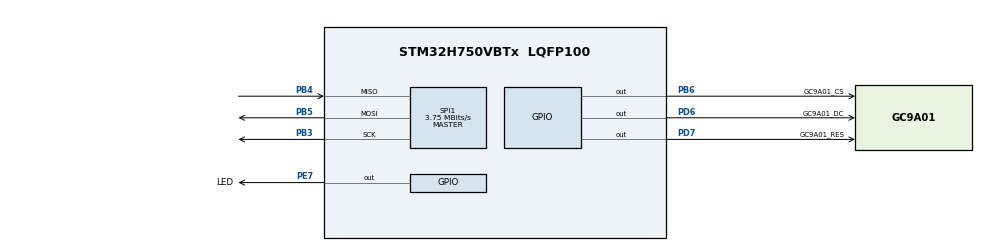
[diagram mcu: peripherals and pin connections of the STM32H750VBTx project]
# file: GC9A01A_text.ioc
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Mcu.Family=STM32H7
Mcu.Name=STM32H750VBTx
Mcu.Package=LQFP100
NVIC.PriorityGroup=NVIC_PRIORITYGROUP_4
NVIC.TIM17_IRQn=true\:15\:0\:false\:false\:true\:false\:true\:true
NVIC.TIM2_IRQn=true\:0\:0\:false\:false\:true\:true\:true\:true
NVIC.TimeBase=TIM17_IRQn
NVIC.TimeBaseIP=TIM17
PA13\ (JTMS/SWDIO).Mode=Serial_Wire
PA13\ (JTMS/SWDIO).Signal=DEBUG_JTMS-SWDIO
PA14\ (JTCK/SWCLK).Mode=Serial_Wire
PA14\ (JTCK/SWCLK).Signal=DEBUG_JTCK-SWCLK
PB3\ (JTDO/TRACESWO).Mode=Full_Duplex_Master
PB3\ (JTDO/TRACESWO).Signal=SPI1_SCK
PB4\ (NJTRST).Mode=Full_Duplex_Master
PB4\ (NJTRST).Signal=SPI1_MISO
PB5.Mode=Full_Duplex_Master
PB5.Signal=SPI1_MOSI
PB6.GPIO_Label=GC9A01_CS
PB6.Signal=GPIO_Output
PD6.GPIO_Label=GC9A01_DC
PD6.Signal=GPIO_Output
PD7.GPIO_Label=GC9A01_RES
PD7.Signal=GPIO_Output
PE7.GPIO_Label=LED
PE7.Signal=GPIO_Output
PH0-OSC_IN\ (PH0).Mode=HSE-External-Oscillator
PH0-OSC_IN\ (PH0).Signal=RCC_OSC_IN
PH1-OSC_OUT\ (PH1).Mode=HSE-External-Oscillator
PH1-OSC_OUT\ (PH1).Signal=RCC_OSC_OUT
ProjectManager.HeapSize=0x200
ProjectManager.StackSize=0x400
ProjectManager.TargetToolchain=STM32CubeIDE
RCC.ADCFreq_Value=50390625
RCC.APB1Freq_Value=120000000
RCC.APB2Freq_Value=120000000
RCC.APB3Freq_Value=120000000
RCC.APB4Freq_Value=120000000
RCC.CortexFreq_Value=240000000
RCC.D1PPRE=RCC_APB3_DIV2
RCC.D2PPRE1=RCC_APB1_DIV2
RCC.D2PPRE2=RCC_APB2_DIV2
RCC.D3PPRE=RCC_APB4_DIV2
RCC.DIVM1=5
RCC.DIVN1=96
RCC.DIVQ1=4
RCC.HCLKFreq_Value=240000000
RCC.PLLFRACN=0
RCC.PLLSourceVirtual=RCC_PLLSOURCE_HSE
RCC.SYSCLKFreq_VALUE=240000000
RCC.SYSCLKSource=RCC_SYSCLKSOURCE_PLLCLK
RCC.USBFreq_Value=120000000
SPI1.BaudRatePrescaler=SPI_BAUDRATEPRESCALER_32
SPI1.CalculateBaudRate=3.75 MBits/s
SPI1.DataSize=SPI_DATASIZE_8BIT
SPI1.Direction=SPI_DIRECTION_2LINES
SPI1.Mode=SPI_MODE_MASTER
SPI1.VirtualType=VM_MASTER
TIM2.Period=999
TIM2.Prescaler=239
VP_HRTIM_VS_hrtimMasterTimerNoOutput.Mode=MasterTimer
VP_SYS_VS_tim17.Mode=TIM17
VP_TIM2_VS_ClockSourceINT.Mode=Internal
board=custom

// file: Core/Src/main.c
/* USER CODE BEGIN Header */
/**
  ******************************************************************************
  * @file           : main.c
  * @brief          : Main program body
  ******************************************************************************
  * @attention
  *
  * Copyright (c) 2024 STMicroelectronics.
  * All rights reserved.
  *
  * This software is licensed under terms that can be found in the LICENSE file
  * in the root directory of this software component.
  * If no LICENSE file comes with this software, it is provided AS-IS.
  *
  ******************************************************************************
  */
/* USER CODE END Header */
#include "main.h"

HRTIM_HandleTypeDef hhrtim;

SPI_HandleTypeDef hspi1;

TIM_HandleTypeDef htim2;

void SystemClock_Config(void);
static void MX_GPIO_Init(void);
static void MX_HRTIM_Init(void);
static void MX_SPI1_Init(void);
static void MX_TIM2_Init(void);

int main(void)
{

  /* MCU Configuration--------------------------------------------------------*/

  /* Reset of all peripherals, Initializes the Flash interface and the Systick. */
  HAL_Init();

  /* Configure the system clock */
  SystemClock_Config();

  /* Initialize all configured peripherals */
  MX_GPIO_Init();
  MX_HRTIM_Init();
  MX_SPI1_Init();
  MX_TIM2_Init();
  /* USER CODE BEGIN 2 */
  setup();
  /* USER CODE END 2 */

  /* Infinite loop */
  while (1)
  {

    /* USER CODE BEGIN 3 */
	  loop();
  }
  /* USER CODE END 3 */
}

void SystemClock_Config(void)
{
  RCC_OscInitTypeDef RCC_OscInitStruct = {0};
  RCC_ClkInitTypeDef RCC_ClkInitStruct = {0};

  /** Supply configuration update enable
  */
  HAL_PWREx_ConfigSupply(PWR_LDO_SUPPLY);

  /** Configure the main internal regulator output voltage
  */
  __HAL_PWR_VOLTAGESCALING_CONFIG(PWR_REGULATOR_VOLTAGE_SCALE2);

  while(!__HAL_PWR_GET_FLAG(PWR_FLAG_VOSRDY)) {}

  /** Initializes the RCC Oscillators according to the specified parameters
  * in the RCC_OscInitTypeDef structure.
  */
  RCC_OscInitStruct.OscillatorType = RCC_OSCILLATORTYPE_HSE;
  RCC_OscInitStruct.HSEState = RCC_HSE_ON;
  RCC_OscInitStruct.PLL.PLLState = RCC_PLL_ON;
  RCC_OscInitStruct.PLL.PLLSource = RCC_PLLSOURCE_HSE;
  RCC_OscInitStruct.PLL.PLLM = 5;
  RCC_OscInitStruct.PLL.PLLN = 96;
  RCC_OscInitStruct.PLL.PLLP = 2;
  RCC_OscInitStruct.PLL.PLLQ = 4;
  RCC_OscInitStruct.PLL.PLLR = 2;
  RCC_OscInitStruct.PLL.PLLRGE = RCC_PLL1VCIRANGE_2;
  RCC_OscInitStruct.PLL.PLLVCOSEL = RCC_PLL1VCOWIDE;
  RCC_OscInitStruct.PLL.PLLFRACN = 0;
  if (HAL_RCC_OscConfig(&RCC_OscInitStruct) != HAL_OK)
  {
    Error_Handler();
  }

  /** Initializes the CPU, AHB and APB buses clocks
  */
  RCC_ClkInitStruct.ClockType = RCC_CLOCKTYPE_HCLK|RCC_CLOCKTYPE_SYSCLK
                              |RCC_CLOCKTYPE_PCLK1|RCC_CLOCKTYPE_PCLK2
                              |RCC_CLOCKTYPE_D3PCLK1|RCC_CLOCKTYPE_D1PCLK1;
  RCC_ClkInitStruct.SYSCLKSource = RCC_SYSCLKSOURCE_PLLCLK;
  RCC_ClkInitStruct.SYSCLKDivider = RCC_SYSCLK_DIV1;
  RCC_ClkInitStruct.AHBCLKDivider = RCC_HCLK_DIV1;
  RCC_ClkInitStruct.APB3CLKDivider = RCC_APB3_DIV2;
  RCC_ClkInitStruct.APB1CLKDivider = RCC_APB1_DIV2;
  RCC_ClkInitStruct.APB2CLKDivider = RCC_APB2_DIV2;
  RCC_ClkInitStruct.APB4CLKDivider = RCC_APB4_DIV2;

  if (HAL_RCC_ClockConfig(&RCC_ClkInitStruct, FLASH_LATENCY_0) != HAL_OK)
  {
    Error_Handler();
  }
}

static void MX_HRTIM_Init(void)
{

  HRTIM_TimeBaseCfgTypeDef pTimeBaseCfg = {0};
  HRTIM_TimerCfgTypeDef pTimerCfg = {0};

  hhrtim.Instance = HRTIM1;
  hhrtim.Init.HRTIMInterruptResquests = HRTIM_IT_NONE;
  hhrtim.Init.SyncOptions = HRTIM_SYNCOPTION_NONE;
  if (HAL_HRTIM_Init(&hhrtim) != HAL_OK)
  {
    Error_Handler();
  }
  pTimeBaseCfg.Period = 0xFFFD;
  pTimeBaseCfg.RepetitionCounter = 0x00;
  pTimeBaseCfg.PrescalerRatio = HRTIM_PRESCALERRATIO_DIV1;
  pTimeBaseCfg.Mode = HRTIM_MODE_CONTINUOUS;
  if (HAL_HRTIM_TimeBaseConfig(&hhrtim, HRTIM_TIMERINDEX_MASTER, &pTimeBaseCfg) != HAL_OK)
  {
    Error_Handler();
  }
  pTimerCfg.InterruptRequests = HRTIM_MASTER_IT_NONE;
  pTimerCfg.DMARequests = HRTIM_MASTER_DMA_NONE;
  pTimerCfg.DMASrcAddress = 0x0000;
  pTimerCfg.DMADstAddress = 0x0000;
  pTimerCfg.DMASize = 0x1;
  pTimerCfg.HalfModeEnable = HRTIM_HALFMODE_DISABLED;
  pTimerCfg.StartOnSync = HRTIM_SYNCSTART_DISABLED;
  pTimerCfg.ResetOnSync = HRTIM_SYNCRESET_DISABLED;
  pTimerCfg.DACSynchro = HRTIM_DACSYNC_NONE;
  pTimerCfg.PreloadEnable = HRTIM_PRELOAD_DISABLED;
  pTimerCfg.UpdateGating = HRTIM_UPDATEGATING_INDEPENDENT;
  pTimerCfg.BurstMode = HRTIM_TIMERBURSTMODE_MAINTAINCLOCK;
  pTimerCfg.RepetitionUpdate = HRTIM_UPDATEONREPETITION_DISABLED;
  if (HAL_HRTIM_WaveformTimerConfig(&hhrtim, HRTIM_TIMERINDEX_MASTER, &pTimerCfg) != HAL_OK)
  {
    Error_Handler();
  }

}

static void MX_SPI1_Init(void)
{

  /* SPI1 parameter configuration*/
  hspi1.Instance = SPI1;
  hspi1.Init.Mode = SPI_MODE_MASTER;
  hspi1.Init.Direction = SPI_DIRECTION_2LINES;
  hspi1.Init.DataSize = SPI_DATASIZE_8BIT;
  hspi1.Init.CLKPolarity = SPI_POLARITY_LOW;
  hspi1.Init.CLKPhase = SPI_PHASE_1EDGE;
  hspi1.Init.NSS = SPI_NSS_SOFT;
  hspi1.Init.BaudRatePrescaler = SPI_BAUDRATEPRESCALER_32;
  hspi1.Init.FirstBit = SPI_FIRSTBIT_MSB;
  hspi1.Init.TIMode = SPI_TIMODE_DISABLE;
  hspi1.Init.CRCCalculation = SPI_CRCCALCULATION_DISABLE;
  hspi1.Init.CRCPolynomial = 0x0;
  hspi1.Init.NSSPMode = SPI_NSS_PULSE_ENABLE;
  hspi1.Init.NSSPolarity = SPI_NSS_POLARITY_LOW;
  hspi1.Init.FifoThreshold = SPI_FIFO_THRESHOLD_01DATA;
  hspi1.Init.TxCRCInitializationPattern = SPI_CRC_INITIALIZATION_ALL_ZERO_PATTERN;
  hspi1.Init.RxCRCInitializationPattern = SPI_CRC_INITIALIZATION_ALL_ZERO_PATTERN;
  hspi1.Init.MasterSSIdleness = SPI_MASTER_SS_IDLENESS_00CYCLE;
  hspi1.Init.MasterInterDataIdleness = SPI_MASTER_INTERDATA_IDLENESS_00CYCLE;
  hspi1.Init.MasterReceiverAutoSusp = SPI_MASTER_RX_AUTOSUSP_DISABLE;
  hspi1.Init.MasterKeepIOState = SPI_MASTER_KEEP_IO_STATE_DISABLE;
  hspi1.Init.IOSwap = SPI_IO_SWAP_DISABLE;
  if (HAL_SPI_Init(&hspi1) != HAL_OK)
  {
    Error_Handler();
  }

}

static void MX_TIM2_Init(void)
{

  TIM_ClockConfigTypeDef sClockSourceConfig = {0};
  TIM_MasterConfigTypeDef sMasterConfig = {0};

  htim2.Instance = TIM2;
  htim2.Init.Prescaler = 239;
  htim2.Init.CounterMode = TIM_COUNTERMODE_UP;
  htim2.Init.Period = 999;
  htim2.Init.ClockDivision = TIM_CLOCKDIVISION_DIV1;
  htim2.Init.AutoReloadPreload = TIM_AUTORELOAD_PRELOAD_DISABLE;
  if (HAL_TIM_Base_Init(&htim2) != HAL_OK)
  {
    Error_Handler();
  }
  sClockSourceConfig.ClockSource = TIM_CLOCKSOURCE_INTERNAL;
  if (HAL_TIM_ConfigClockSource(&htim2, &sClockSourceConfig) != HAL_OK)
  {
    Error_Handler();
  }
  sMasterConfig.MasterOutputTrigger = TIM_TRGO_RESET;
  sMasterConfig.MasterSlaveMode = TIM_MASTERSLAVEMODE_DISABLE;
  if (HAL_TIMEx_MasterConfigSynchronization(&htim2, &sMasterConfig) != HAL_OK)
  {
    Error_Handler();
  }

}

static void MX_GPIO_Init(void)
{
  GPIO_InitTypeDef GPIO_InitStruct = {0};

  /* GPIO Ports Clock Enable */
  __HAL_RCC_GPIOH_CLK_ENABLE();
  __HAL_RCC_GPIOE_CLK_ENABLE();
  __HAL_RCC_GPIOA_CLK_ENABLE();
  __HAL_RCC_GPIOD_CLK_ENABLE();
  __HAL_RCC_GPIOB_CLK_ENABLE();

  /*Configure GPIO pin Output Level */
  HAL_GPIO_WritePin(LED_GPIO_Port, LED_Pin, GPIO_PIN_RESET);

  /*Configure GPIO pin Output Level */
  HAL_GPIO_WritePin(GPIOD, GC9A01_DC_Pin|GC9A01_RES_Pin, GPIO_PIN_RESET);

  /*Configure GPIO pin Output Level */
  HAL_GPIO_WritePin(GC9A01_CS_GPIO_Port, GC9A01_CS_Pin, GPIO_PIN_RESET);

  /*Configure GPIO pin : LED_Pin */
  GPIO_InitStruct.Pin = LED_Pin;
  GPIO_InitStruct.Mode = GPIO_MODE_OUTPUT_PP;
  GPIO_InitStruct.Pull = GPIO_NOPULL;
  GPIO_InitStruct.Speed = GPIO_SPEED_FREQ_LOW;
  HAL_GPIO_Init(LED_GPIO_Port, &GPIO_InitStruct);

  /*Configure GPIO pins : GC9A01_DC_Pin GC9A01_RES_Pin */
  GPIO_InitStruct.Pin = GC9A01_DC_Pin|GC9A01_RES_Pin;
  GPIO_InitStruct.Mode = GPIO_MODE_OUTPUT_PP;
  GPIO_InitStruct.Pull = GPIO_NOPULL;
  GPIO_InitStruct.Speed = GPIO_SPEED_FREQ_LOW;
  HAL_GPIO_Init(GPIOD, &GPIO_InitStruct);

  /*Configure GPIO pin : GC9A01_CS_Pin */
  GPIO_InitStruct.Pin = GC9A01_CS_Pin;
  GPIO_InitStruct.Mode = GPIO_MODE_OUTPUT_PP;
  GPIO_InitStruct.Pull = GPIO_NOPULL;
  GPIO_InitStruct.Speed = GPIO_SPEED_FREQ_LOW;
  HAL_GPIO_Init(GC9A01_CS_GPIO_Port, &GPIO_InitStruct);

}

void HAL_TIM_PeriodElapsedCallback(TIM_HandleTypeDef *htim)
{
  /* USER CODE BEGIN Callback 0 */
  if (htim->Instance == TIM2) {
  }
  /* USER CODE END Callback 0 */
  if (htim->Instance == TIM17) {
    HAL_IncTick();
  }
}

void Error_Handler(void)
{
  __disable_irq();
  while (1)
  {
  }
}
